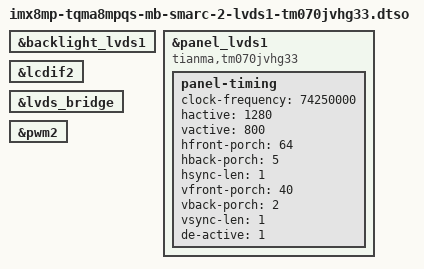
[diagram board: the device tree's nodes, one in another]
// SPDX-License-Identifier: (GPL-2.0-or-later OR MIT)
/*
 * Copyright (c) 2025-2026 TQ-Systems GmbH <linux@ew.tq-group.com>,
 * D-82229 Seefeld, Germany.
 * Author: Paul Gerber
 */

/dts-v1/;
/plugin/;

&backlight_lvds1 {
	status = "okay";
};

&panel_lvds1{
	compatible = "tianma,tm070jvhg33";
	status = "okay";

	panel-timing {
		clock-frequency = <74250000>;
		hactive = <1280>;
		vactive = <800>;
		hfront-porch = <64>;
		hback-porch = <5>;
		hsync-len = <1>;
		vfront-porch = <40>;
		vback-porch = <2>;
		vsync-len = <1>;
		de-active = <1>;
	};
};

&lcdif2 {
	status = "okay";
};

&lvds_bridge {
	status = "okay";
};

&pwm2 {
	status = "okay";
};
